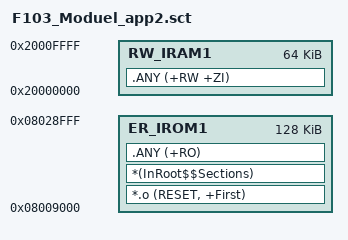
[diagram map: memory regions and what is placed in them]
; *************************************************************
; *** Scatter-Loading Description File generated by uVision ***
; *************************************************************

; 这里的加载区地址写 0x20000000，是为了让编译器生成的
; 所有绝对地址、跳转表、变量引用都基于 RAM。
;LR_IROM1 0x20000000 0x00010000  {    

  ;ER_RAM 0x20000000 0x00010000  {  
   ;*.o (RESET, +First)        ; 向量表放在 RAM 起始
   ;.ANY (+RO)                  ; 代码段
   ;.ANY (+RW +ZI)              ; 变量段
  ;}
;}

;LR_IROM1 0x20000000 0x00006000  {    ; load region size_region
  ;ER_IROM1 0x20000000 0x00006000  {  ; load address = execution address
   ;*.o (RESET, +First)
   ;*(InRoot$$Sections)
   ;.ANY (+RO)
  ;}
  ;RW_IRAM1 0x20006000 0x00003000  {  ; RW data
   ;.ANY (+RW +ZI)
  ;}
;}


LR_IROM1 0x08009000 0x00020000  {    ; load region size_region
  ER_IROM1 0x08009000 0x00020000  {  ; load address = execution address
   *.o (RESET, +First)
   *(InRoot$$Sections)
   .ANY (+RO)
  }
  RW_IRAM1 0x20000000 0x00010000  {  ; RW data
   .ANY (+RW +ZI)
  }
}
